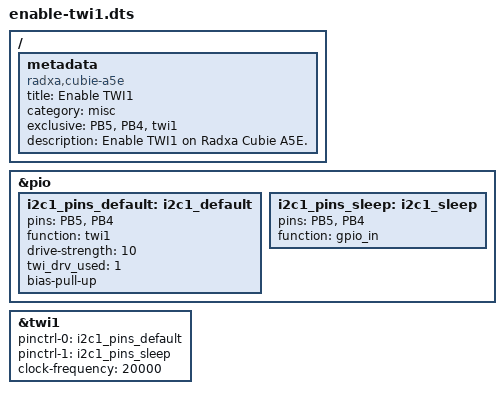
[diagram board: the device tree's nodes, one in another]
/dts-v1/;
/plugin/;
/*
	compatible = "allwinner,sun55i-a523", "allwinner,sun55i-a527";
*/

/ {
    metadata {
        title = "Enable TWI1";
        compatible = "radxa,cubie-a5e";
        category = "misc";
        exclusive = "PB5", "PB4", "twi1";
        description = "Enable TWI1 on Radxa Cubie A5E.";
    };
};

&pio {
    i2c1_pins_default: i2c1_default {
        pins = "PB5", "PB4";
        function = "twi1";
        drive-strength = <10>;
        twi_drv_used = <1>;
        bias-pull-up;
    };
    i2c1_pins_sleep: i2c1_sleep {
        pins = "PB5", "PB4";
        function = "gpio_in";
    };
};

&twi1 {
    pinctrl-names = "default", "sleep";
    pinctrl-0 = <&i2c1_pins_default>;
    pinctrl-1 = <&i2c1_pins_sleep>;
    clock-frequency = <20000>;
    status = "okay";
};
